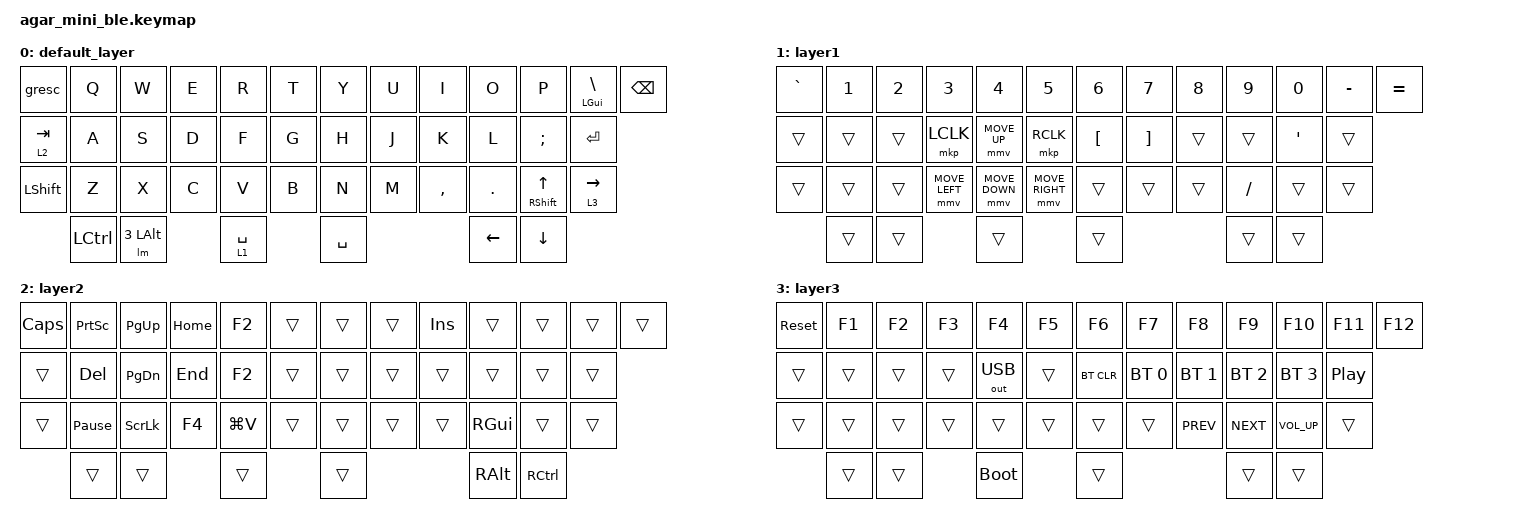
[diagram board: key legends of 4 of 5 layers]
/*
 * Copyright (c) 2021 The ZMK Contributors
 *
 * SPDX-License-Identifier: MIT
 */

#include "./boards/shields/klink_kbd/common.keymap"
#include <behaviors.dtsi>
#include <dt-bindings/zmk/bt.h>
#include <dt-bindings/zmk/keys.h>
#include <dt-bindings/zmk/outputs.h>
#include <dt-bindings/zmk/pointing.h>

/ {
    behaviors {
        lm: layer_mod {
            compatible = "zmk,behavior-macro-two-param";
            #binding-cells = <2>;
            wait-ms = <10>;
            tap-ms = <0>;
            bindings =
                <&macro_param_1to1>,
                <&macro_press>,
                <&mo MACRO_PLACEHOLDER &macro_param_2to1>,
                <&macro_press>,
                <&kp MACRO_PLACEHOLDER>,
                <&macro_pause_for_release>,
                <&macro_param_2to1>,
                <&macro_release>,
                <&kp MACRO_PLACEHOLDER &macro_param_1to1>,
                <&macro_release>,
                <&mo MACRO_PLACEHOLDER>;
        };

        test: test {
            compatible = "zmk,behavior-hold-tap";
            label = "TEST";
            bindings = <&bootloader>, <&lt>;

            #binding-cells = <2>;
            tapping-term-ms = <10>;
        };
    };

    macros {
    };

    keymap {
        compatible = "zmk,keymap";

        default_layer {
            bindings = <
&gresc     &kp Q      &kp W           &kp E  &kp R        &kp T  &kp Y      &kp U  &kp I      &kp O           &kp P                &mt LGUI BACKSLASH  &kp BSPC
&lt 2 TAB  &kp A      &kp S           &kp D  &kp F        &kp G  &kp H      &kp J  &kp K      &kp L           &kp SEMI             &kp RET
&kp LSHFT  &kp Z      &kp X           &kp C  &kp V        &kp B  &kp N      &kp M  &kp COMMA  &kp DOT         &mt RSHIFT UP_ARROW  &lt 3 RIGHT_ARROW
           &kp LCTRL  &lm 3 LEFT_ALT         &lt 1 SPACE         &kp SPACE                    &kp LEFT_ARROW  &kp DOWN_ARROW
            >;
        };

        layer1 {
            bindings = <
&kp GRAVE  &kp N1  &kp N2  &kp N3          &kp N4          &kp N5           &kp N6            &kp N7             &kp N8  &kp N9     &kp N0            &kp MINUS  &kp EQUAL
&trans     &trans  &trans  &mkp LCLK       &mmv MOVE_UP    &mkp RCLK        &kp LEFT_BRACKET  &kp RIGHT_BRACKET  &trans  &trans     &kp SINGLE_QUOTE  &trans
&trans     &trans  &trans  &mmv MOVE_LEFT  &mmv MOVE_DOWN  &mmv MOVE_RIGHT  &trans            &trans             &trans  &kp SLASH  &trans            &trans
           &trans  &trans                  &trans                           &trans                                       &trans     &trans
            >;
        };

        layer2 {
            bindings = <
&kp CAPSLOCK  &kp PRINTSCREEN  &kp PAGE_UP     &kp HOME  &kp F2     &trans  &trans  &trans  &kp INSERT  &trans    &trans     &trans  &trans
&trans        &kp DELETE       &kp PAGE_DOWN   &kp END   &kp F2     &trans  &trans  &trans  &trans      &trans    &trans     &trans
&trans        &kp PAUSE_BREAK  &kp SCROLLLOCK  &kp F4    &kp LG(V)  &trans  &trans  &trans  &trans      &kp RGUI  &trans     &trans
              &trans           &trans                    &trans             &trans                      &kp RALT  &kp RCTRL
            >;
        };

        layer3 {
            bindings = <
&sys_reset  &kp F1  &kp F2  &kp F3  &kp F4        &kp F5  &kp F6      &kp F7        &kp F8        &kp F9        &kp F10       &kp F11           &kp F12
&trans      &trans  &trans  &trans  &out OUT_USB  &trans  &bt BT_CLR  &bt BT_SEL 0  &bt BT_SEL 1  &bt BT_SEL 2  &bt BT_SEL 3  &kp C_PLAY_PAUSE
&trans      &trans  &trans  &trans  &trans        &trans  &trans      &trans        &kp C_PREV    &kp C_NEXT    &kp C_VOL_UP  &trans
            &trans  &trans          &bootloader           &trans                                  &trans        &trans
            >;
        };

        layer_4 {
            bindings = <
&trans  &trans  &trans  &trans  &trans  &trans  &trans  &trans  &trans  &trans  &trans  &trans  &trans
&trans  &trans  &trans  &trans  &trans  &trans  &trans  &trans  &trans  &trans  &trans  &trans
&trans  &trans  &trans  &trans  &trans  &trans  &trans  &trans  &trans  &trans  &trans  &trans
        &trans  &trans          &trans          &trans                  &trans  &trans          &trans
            >;
        };
    };
};
